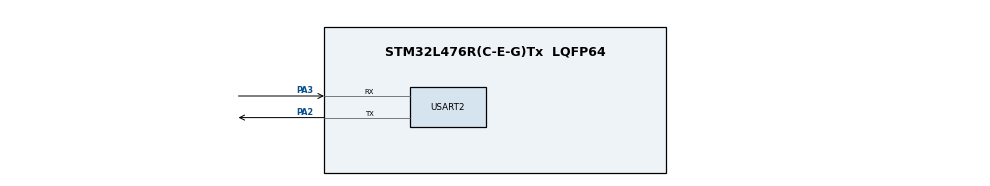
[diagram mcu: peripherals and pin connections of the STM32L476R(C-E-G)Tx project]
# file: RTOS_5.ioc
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FREERTOS.Tasks01=defaultTask,0,128,StartDefaultTask,Default,NULL,Dynamic,NULL,NULL
Mcu.Family=STM32L4
Mcu.Name=STM32L476R(C-E-G)Tx
Mcu.Package=LQFP64
NVIC.PriorityGroup=NVIC_PRIORITYGROUP_4
NVIC.TIM1_UP_TIM16_IRQn=true\:0\:0\:false\:false\:true\:false\:false\:true
NVIC.TimeBase=TIM1_UP_TIM16_IRQn
NVIC.TimeBaseIP=TIM1
NVIC.USART2_IRQn=true\:5\:0\:false\:false\:true\:true\:true\:true
PA2.Mode=Asynchronous
PA2.Signal=USART2_TX
PA3.Mode=Asynchronous
PA3.Signal=USART2_RX
ProjectManager.HeapSize=0x200
ProjectManager.StackSize=0x400
ProjectManager.TargetToolchain=TrueSTUDIO
RCC.HSE_VALUE=8000000
RCC.HSI_VALUE=16000000
RCC.LSE_VALUE=32768
RCC.MSI_VALUE=4000000
RCC.VCOOutputFreq_Value=32000000
USART2.VirtualMode-Asynchronous=VM_ASYNC
VP_FREERTOS_VS_CMSIS_V1.Mode=CMSIS_V1
VP_SYS_VS_tim1.Mode=TIM1
board=custom

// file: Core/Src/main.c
/* USER CODE BEGIN Header */
/**
  ******************************************************************************
  * @file           : main.c
  * @brief          : Main program body
  ******************************************************************************
  * @attention
  *
  * <h2><center>&copy; Copyright (c) 2021 STMicroelectronics.
  * All rights reserved.</center></h2>
  *
  * This software component is licensed by ST under Ultimate Liberty license
  * SLA0044, the "License"; You may not use this file except in compliance with
  * the License. You may obtain a copy of the License at:
  *                             www.st.com/SLA0044
  *
  ******************************************************************************
  */
/* USER CODE END Header */
#include "main.h"
//#include "cmsis_os.h"

/* USER CODE BEGIN Includes */
#include "FreeRTOS.h"
#include "task.h"
#include "timers.h"
#include "queue.h"
#include "semphr.h"
#include "event_groups.h"

#include "string.h"
#include "stdio.h"
/* USER CODE END Includes */

UART_HandleTypeDef huart2;

void SystemClock_Config(void);
static void MX_GPIO_Init(void);
static void MX_USART2_UART_Init(void);

/* USER CODE BEGIN 0 */
xTaskHandle Sender_HPT_Handler;
xTaskHandle Sender_LPT_Handler;
xTaskHandle Receiver_Handler;

/**************** QUEUE HANDLER ***********************/
xQueueHandle SimpleQueue;

void Sender_HPT_Task(void *argument);
void Sender_LPT_Task(void *argument);
void Receiver_Task(void *argument);

uint8_t Rx_data;
/* USER CODE END 0 */

int main(void)
{

  /* MCU Configuration--------------------------------------------------------*/

  /* Reset of all peripherals, Initializes the Flash interface and the Systick. */
  HAL_Init();

  /* Configure the system clock */
  SystemClock_Config();

  /* Initialize all configured peripherals */
  MX_GPIO_Init();
  MX_USART2_UART_Init();
  /* USER CODE BEGIN 2 */
  /************************* Create Integer Queue ****************************/
    SimpleQueue = xQueueCreate(5, sizeof (int));
    if (SimpleQueue == 0)  // Queue not created
    {
  	  char *str = "Unable to create Integer Queue\n\n";
  	  HAL_UART_Transmit(&huart2, (uint8_t *)str, strlen (str), HAL_MAX_DELAY);
    }
    else
    {
  	  char *str = "Integer Queue Created successfully\n\n";
  	  HAL_UART_Transmit(&huart2, (uint8_t *)str, strlen (str), HAL_MAX_DELAY);
    }

	 xTaskCreate(Sender_HPT_Task,"HPT_SEND",128,NULL,3,&Sender_HPT_Handler);
	 xTaskCreate(Sender_LPT_Task,"LPT_SEND",128,(void *)111,2,&Sender_LPT_Handler);
	 xTaskCreate(Receiver_Task,"Receive",128,NULL,1,&Receiver_Handler);

	 HAL_UART_Receive_IT(&huart2,&Rx_data,1);

	 vTaskStartScheduler();
  /* USER CODE END 2 */

  /* We should never get here as control is now taken by the scheduler */
  /* Infinite loop */
  while (1)
  {

  }
}

void SystemClock_Config(void)
{
  RCC_OscInitTypeDef RCC_OscInitStruct = {0};
  RCC_ClkInitTypeDef RCC_ClkInitStruct = {0};
  RCC_PeriphCLKInitTypeDef PeriphClkInit = {0};

  /** Initializes the RCC Oscillators according to the specified parameters
  * in the RCC_OscInitTypeDef structure.
  */
  RCC_OscInitStruct.OscillatorType = RCC_OSCILLATORTYPE_MSI;
  RCC_OscInitStruct.MSIState = RCC_MSI_ON;
  RCC_OscInitStruct.MSICalibrationValue = 0;
  RCC_OscInitStruct.MSIClockRange = RCC_MSIRANGE_6;
  RCC_OscInitStruct.PLL.PLLState = RCC_PLL_NONE;
  if (HAL_RCC_OscConfig(&RCC_OscInitStruct) != HAL_OK)
  {
    Error_Handler();
  }
  /** Initializes the CPU, AHB and APB buses clocks
  */
  RCC_ClkInitStruct.ClockType = RCC_CLOCKTYPE_HCLK|RCC_CLOCKTYPE_SYSCLK
                              |RCC_CLOCKTYPE_PCLK1|RCC_CLOCKTYPE_PCLK2;
  RCC_ClkInitStruct.SYSCLKSource = RCC_SYSCLKSOURCE_MSI;
  RCC_ClkInitStruct.AHBCLKDivider = RCC_SYSCLK_DIV1;
  RCC_ClkInitStruct.APB1CLKDivider = RCC_HCLK_DIV1;
  RCC_ClkInitStruct.APB2CLKDivider = RCC_HCLK_DIV1;

  if (HAL_RCC_ClockConfig(&RCC_ClkInitStruct, FLASH_LATENCY_0) != HAL_OK)
  {
    Error_Handler();
  }
  PeriphClkInit.PeriphClockSelection = RCC_PERIPHCLK_USART2;
  PeriphClkInit.Usart2ClockSelection = RCC_USART2CLKSOURCE_PCLK1;
  if (HAL_RCCEx_PeriphCLKConfig(&PeriphClkInit) != HAL_OK)
  {
    Error_Handler();
  }
  /** Configure the main internal regulator output voltage
  */
  if (HAL_PWREx_ControlVoltageScaling(PWR_REGULATOR_VOLTAGE_SCALE1) != HAL_OK)
  {
    Error_Handler();
  }
}

static void MX_USART2_UART_Init(void)
{

  huart2.Instance = USART2;
  huart2.Init.BaudRate = 115200;
  huart2.Init.WordLength = UART_WORDLENGTH_8B;
  huart2.Init.StopBits = UART_STOPBITS_1;
  huart2.Init.Parity = UART_PARITY_NONE;
  huart2.Init.Mode = UART_MODE_TX_RX;
  huart2.Init.HwFlowCtl = UART_HWCONTROL_NONE;
  huart2.Init.OverSampling = UART_OVERSAMPLING_16;
  huart2.Init.OneBitSampling = UART_ONE_BIT_SAMPLE_DISABLE;
  huart2.AdvancedInit.AdvFeatureInit = UART_ADVFEATURE_NO_INIT;
  if (HAL_UART_Init(&huart2) != HAL_OK)
  {
    Error_Handler();
  }

}

static void MX_GPIO_Init(void)
{

  /* GPIO Ports Clock Enable */
  __HAL_RCC_GPIOA_CLK_ENABLE();

}

/* USER CODE BEGIN 4 */
void Sender_HPT_Task (void *argument)
{
	int i=222;
	uint32_t TickDelay = pdMS_TO_TICKS(2000);
	while (1)
	{
		char *str="Enter sender_HPT task\r\n about to SEND a number to the queue\r\n";
		HAL_UART_Transmit(&huart2,(uint8_t *)str,strlen(str),HAL_MAX_DELAY);

		if (xQueueSend(SimpleQueue, &i, portMAX_DELAY) == pdPASS)
		{
			char *str2 = " Successfully sent the number to the queue\r\nLeaving SENDER_HPT Task\r\n\n\n";
			HAL_UART_Transmit(&huart2, (uint8_t *)str2, strlen (str2), HAL_MAX_DELAY);
		}
		vTaskDelay(TickDelay);
	}
}

void Sender_LPT_Task (void *argument)
{
	int ToSend;
	uint32_t TickDelay = pdMS_TO_TICKS(1000);
	while (1)
	{
		ToSend=(int) argument;
		char *str="Enter sender_LPT task\r\n about to SEND a number to the queue\r\n";
		HAL_UART_Transmit(&huart2,(uint8_t *)str,strlen(str),HAL_MAX_DELAY);

		xQueueSend(SimpleQueue, &ToSend, portMAX_DELAY);

	    char *str2 = " Successfully sent the number to the queue\r\nLeaving SENDER_LPT Task\r\n\n\n";
		HAL_UART_Transmit(&huart2, (uint8_t *)str2, strlen (str2), HAL_MAX_DELAY);

		vTaskDelay(TickDelay);
	}
}

void Receiver_Task (void *argument)
{
	int received=0;
	uint32_t TickDelay = pdMS_TO_TICKS(3000);
	while (1)
	{
		char str[100];
		strcpy(str,"Enter receiver task\r\n about to RECEIVE a number to the queue\r\n");
		HAL_UART_Transmit(&huart2,(uint8_t *)str,strlen(str),HAL_MAX_DELAY);

		if (xQueueReceive(SimpleQueue, &received, portMAX_DELAY) != pdTRUE)
		{
			HAL_UART_Transmit(&huart2, (uint8_t *)"Error in Receiving from Queue\r\n\n", 31, 1000);
		}
		else
		{
			sprintf(str, " Successfully RECEIVED the number %d to the queue\r\nLeaving RECEIVER Task\r\n\n\n",received);
			HAL_UART_Transmit(&huart2, (uint8_t *)str, strlen (str), HAL_MAX_DELAY);
		}
		vTaskDelay(TickDelay);
	}
}

void HAL_UART_RxCpltCallback(UART_HandleTypeDef *huart)
{
	HAL_UART_Receive_IT(huart, &Rx_data, 1);
	int ToSend = 123456789;
	if (Rx_data == 'r')
	{
		 /* The xHigherPriorityTaskWoken parameter must be initialized to pdFALSE as
		 it will get set to pdTRUE inside the interrupt safe API function if a
		 context switch is required. */
		BaseType_t xHigherPriorityTaskWoken = pdFALSE;

		if (xQueueSendToFrontFromISR(SimpleQueue, &ToSend, &xHigherPriorityTaskWoken) == pdPASS)
		{
			HAL_UART_Transmit(huart, (uint8_t *)"\r\n\nSent from ISR\r\n\n", 17, 500);
		}

		/* Pass the xHigherPriorityTaskWoken value into portEND_SWITCHING_ISR(). If
		 xHigherPriorityTaskWoken was set to pdTRUE inside xSemaphoreGiveFromISR()
		 then calling portEND_SWITCHING_ISR() will request a context switch. If
		 xHigherPriorityTaskWoken is still pdFALSE then calling
		 portEND_SWITCHING_ISR() will have no effect */

		portEND_SWITCHING_ISR(xHigherPriorityTaskWoken);
	}
}

/* USER CODE END 4 */

 /**
  * @brief  Period elapsed callback in non blocking mode
  * @note   This function is called  when TIM1 interrupt took place, inside
  * HAL_TIM_IRQHandler(). It makes a direct call to HAL_IncTick() to increment
  * a global variable "uwTick" used as application time base.
  * @param  htim : TIM handle
  * @retval None
  */
void HAL_TIM_PeriodElapsedCallback(TIM_HandleTypeDef *htim)
{
  if (htim->Instance == TIM1) {
    HAL_IncTick();
  }
}

void Error_Handler(void)
{
  __disable_irq();
  while (1)
  {
  }
}

/************************ (C) COPYRIGHT STMicroelectronics *****END OF FILE****/
